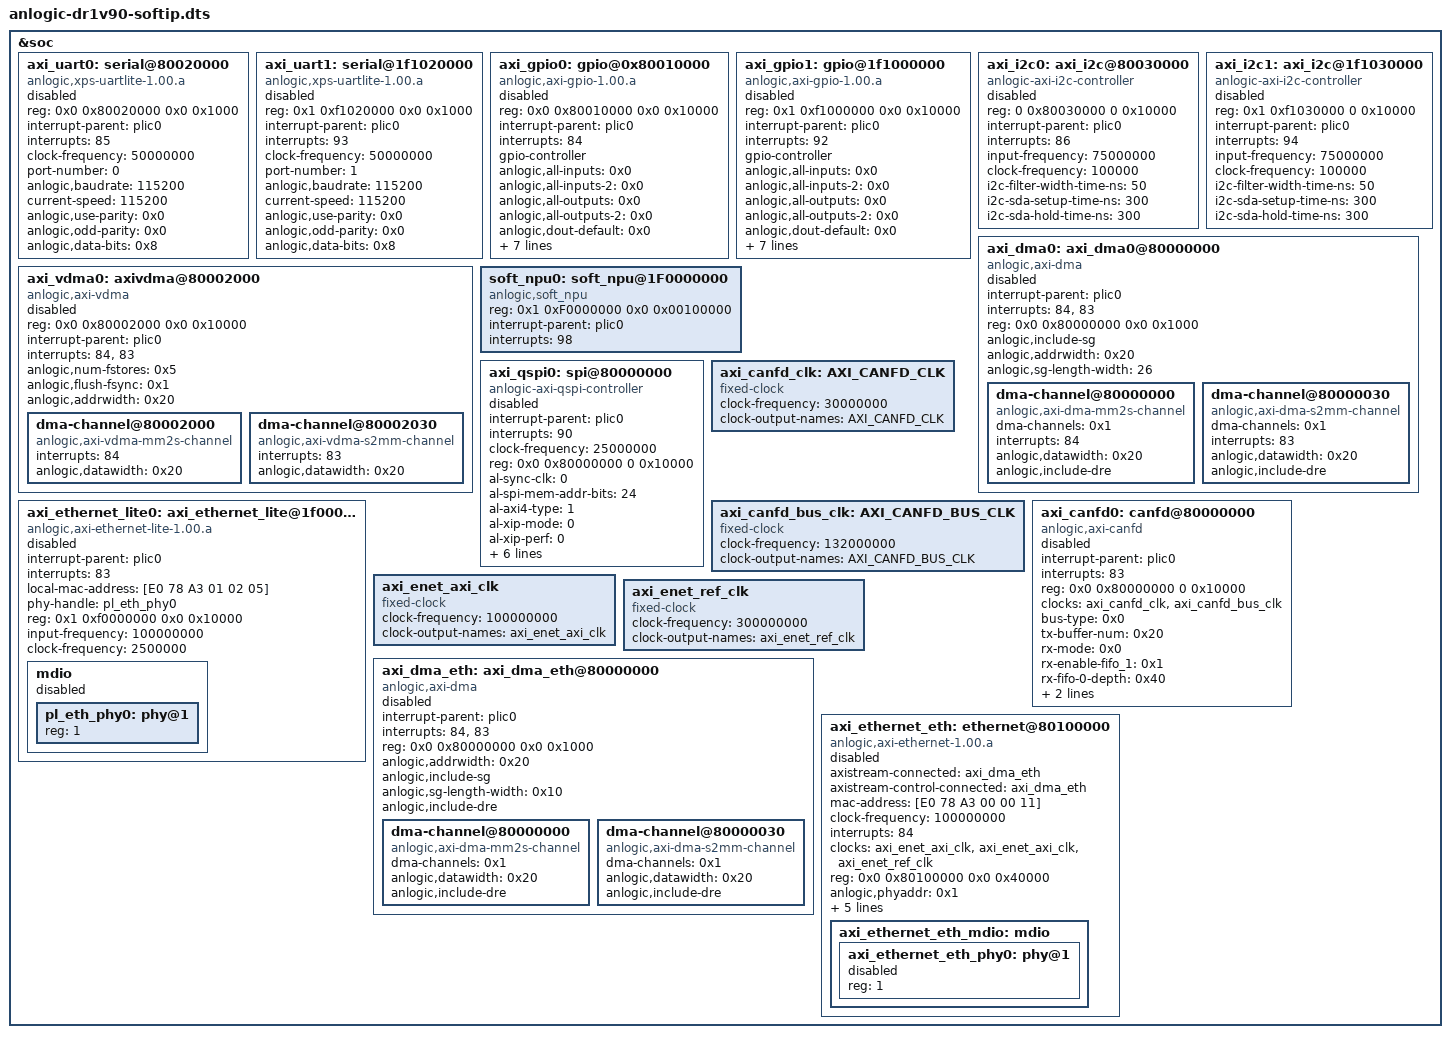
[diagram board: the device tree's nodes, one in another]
// SPDX-License-Identifier: (GPL-2.0+ OR MIT)

&soc {
	axi_uart0: serial@80020000 {
		compatible = "anlogic,xps-uartlite-1.00.a";
		reg = <0x0 0x80020000 0x0 0x1000>;
		interrupt-parent = <&plic0>;
		interrupts = <85>; /* BM 116 */
		clock-frequency = <50000000>;
		port-number = <0>;
		anlogic,baudrate = <115200>;
		current-speed = <115200>;
		anlogic,use-parity = <0x0>;
		anlogic,odd-parity = <0x0>;
		anlogic,data-bits = <0x8>;
		status = "disabled";
	};

	axi_uart1: serial@1f1020000 {
		compatible = "anlogic,xps-uartlite-1.00.a";
		reg = <0x1 0xf1020000 0x0 0x1000>;
		interrupt-parent = <&plic0>;
		interrupts = <93>; /* BM 124 */
		clock-frequency = <50000000>;
		port-number = <1>;
		anlogic,baudrate = <115200>;
		current-speed = <115200>;
		anlogic,use-parity = <0x0>;
		anlogic,odd-parity = <0x0>;
		anlogic,data-bits = <0x8>;
		status = "disabled";
	};

	axi_gpio0: gpio@0x80010000 {
		compatible = "anlogic,axi-gpio-1.00.a";
		reg = <0x0 0x80010000 0x0 0x10000>;
		interrupt-parent = <&plic0>;
		interrupts = <84>; /* BM 115 */
		#gpio-cells = <2>;
		#interrupt-cells = <0x2>;
		gpio-controller;
		anlogic,all-inputs = <0x0>;
		anlogic,all-inputs-2 = <0x0>;
		anlogic,all-outputs = <0x0>;
		anlogic,all-outputs-2 = <0x0>;
		anlogic,dout-default = <0x0>;
		anlogic,dout-default-2 = <0x0>;
		anlogic,gpio-width = <0x20>;
		anlogic,gpio2-width = <0x20>;
		anlogic,interrupt-present = <0x1>;
		anlogic,is-dual = <0x1>;
		anlogic,tri-default = <0xFFFFFFFF>;
		anlogic,tri-default-2 = <0xFFFFFFFF>;
		status = "disabled";
	};

	axi_gpio1: gpio@1f1000000 {
		compatible = "anlogic,axi-gpio-1.00.a";
		reg = <0x1 0xf1000000 0x0 0x10000>;
		interrupt-parent = <&plic0>;
		interrupts = <92>; /* BM 123 */
		#gpio-cells = <2>;
		#interrupt-cells = <0x2>;
		gpio-controller;
		anlogic,all-inputs = <0x0>;
		anlogic,all-inputs-2 = <0x0>;
		anlogic,all-outputs = <0x0>;
		anlogic,all-outputs-2 = <0x0>;
		anlogic,dout-default = <0x0>;
		anlogic,dout-default-2 = <0x0>;
		anlogic,gpio-width = <0x20>;
		anlogic,gpio2-width = <0x20>;
		anlogic,interrupt-present = <0x1>;
		anlogic,is-dual = <0x1>;
		anlogic,tri-default = <0xFFFFFFFF>;
		anlogic,tri-default-2 = <0xFFFFFFFF>;
		status = "disabled";
	};

	axi_i2c0: axi_i2c@80030000 {
		compatible = "anlogic-axi-i2c-controller";
		reg = <0 0x80030000 0 0x10000>;
		interrupt-parent = <&plic0>;
		interrupts = <86>;
		input-frequency = <75000000>;
		clock-frequency = <100000>;
		i2c-filter-width-time-ns = <50>;
		i2c-sda-setup-time-ns = <300>;
		i2c-sda-hold-time-ns = <300>;
		#address-cells = <1>;
		#size-cells = <0>;
		status = "disabled";
	};

	axi_i2c1: axi_i2c@1f1030000 {
		compatible = "anlogic-axi-i2c-controller";
		reg = <0x1 0xf1030000 0 0x10000>;
		interrupt-parent = <&plic0>;
		interrupts = <94>;
		input-frequency = <75000000>;
		clock-frequency = <100000>;
		i2c-filter-width-time-ns = <50>;
		i2c-sda-setup-time-ns = <300>;
		i2c-sda-hold-time-ns = <300>;
		#address-cells = <1>;
		#size-cells = <0>;
		status = "disabled";
	};

	axi_dma0: axi_dma0@80000000 {
		#dma-cells = <1>;
		compatible = "anlogic,axi-dma";
		interrupt-parent = <&plic0>;
		interrupts = <84>, <83>;
		reg = <0x0 0x80000000 0x0 0x1000>;
		anlogic,include-sg;
		anlogic,addrwidth = <0x20>;
		anlogic,sg-length-width = <26>;
		status = "disabled";

		dma-channel@80000000 {
			compatible = "anlogic,axi-dma-mm2s-channel";
			dma-channels = <0x1>;
			interrupts = <84>;
			anlogic,datawidth = <0x20>;
			anlogic,include-dre;
		};

		dma-channel@80000030 {
			compatible = "anlogic,axi-dma-s2mm-channel";
			dma-channels = <0x1>;
			interrupts = <83>;
			anlogic,datawidth = <0x20>;
			anlogic,include-dre;
		};
	};

	axi_vdma0: axivdma@80002000 {
		compatible = "anlogic,axi-vdma";
		#dma-cells = <1>;
		reg = <0x0 0x80002000 0x0 0x10000 >;
		interrupt-parent = <&plic0>;
		interrupts = <84>, <83>;
		anlogic,num-fstores = <0x5>;
		anlogic,flush-fsync = <0x1>;
		anlogic,addrwidth = <0x20>;
		status = "disabled";

		dma-channel@80002000 {
			compatible = "anlogic,axi-vdma-mm2s-channel";
			interrupts = <84>;
			anlogic,datawidth = <0x20>;
		} ;

		dma-channel@80002030 {
			compatible = "anlogic,axi-vdma-s2mm-channel";
			interrupts = <83>;
			anlogic,datawidth = <0x20>;
		} ;
	} ;

	soft_npu0: soft_npu@1F0000000 {
		compatible = "anlogic,soft_npu";
		reg = <0x1 0xF0000000 0x0 0x00100000>;
		interrupt-parent = <&plic0>;
		interrupts = <98>;
	};

	axi_qspi0: spi@80000000 {
		compatible = "anlogic-axi-qspi-controller";
		interrupt-parent = <&plic0>;
		interrupts = <90>;
		clock-frequency = <25000000>;
		reg = <0x0 0x80000000 0 0x10000>;
		#address-cells = <1>;
		#size-cells = <0>;
		status = "disable";

		al-sync-clk = <0>;
		al-spi-mem-addr-bits = <24>;
		al-axi4-type = <1>;
		al-xip-mode = <0>;
		al-xip-perf = <0>;
		al-fifo-depth = <256>;
		al-sck-ratio = <2>;
		al-num-ss-bits = <1>;
		al-num-trans-bits = <8>;
		al-spi-mode = <0>;
		al-spi-memory = <3>;
	};

	axi_ethernet_lite0: axi_ethernet_lite@1f0000000 {
		compatible = "anlogic,axi-ethernet-lite-1.00.a";
		device_type = "network";
		interrupt-parent = <&plic0>;
		interrupts = <83>;
		local-mac-address = [E0 78 A3 01 02 05];
		phy-handle = <&pl_eth_phy0>;
		reg = <0x1 0xf0000000 0x0 0x10000>;
		input-frequency = <100000000>;
		clock-frequency = <2500000>;
		status = "disabled";

		mdio {
			#address-cells = <1>;
			#size-cells = <0>;
			status = "disabled";
			pl_eth_phy0: phy@1 {
					device_type = "ethernet-phy";
					reg = <1>;
			} ;
		};
	};

	axi_canfd_clk: AXI_CANFD_CLK {
		#clock-cells = <0>;
		compatible = "fixed-clock";
		clock-frequency = <30000000>;
		clock-output-names = "AXI_CANFD_CLK";
	};

	axi_canfd_bus_clk: AXI_CANFD_BUS_CLK {
		#clock-cells = <0>;
		compatible = "fixed-clock";
		clock-frequency = <132000000>;
		clock-output-names = "AXI_CANFD_BUS_CLK";
	};

	axi_canfd0: canfd@80000000 {
		compatible = "anlogic,axi-canfd";
		interrupt-parent = <&plic0>;
		interrupts = <83>;
		reg = <0x0 0x80000000 0 0x10000>;
		#address-cells = <1>;
		#size-cells = <0>;
		status = "disabled";

		clocks = <&axi_canfd_clk>, <&axi_canfd_bus_clk>;
		clock-names = "can_clk", "bus_clk";
		bus-type = <0x0>;
		tx-buffer-num = <0x20>;
		rx-mode = <0x0>;
		rx-enable-fifo_1 = <0x1>;
		rx-fifo-0-depth = <0x40>;
		rx-fifo-1-depth = <0x40>;
		rx-buffer-num = <0x30>;
	};

	axi_enet_axi_clk: axi_enet_axi_clk {
		#clock-cells = <0>;
		compatible = "fixed-clock";
		clock-frequency = <100000000>;
		clock-output-names = "axi_enet_axi_clk";
	};

	axi_enet_ref_clk: axi_enet_ref_clk {
		#clock-cells = <0>;
		compatible = "fixed-clock";
		clock-frequency = <300000000>;
		clock-output-names = "axi_enet_ref_clk";
	};

	axi_dma_eth: axi_dma_eth@80000000 {
		#dma-cells = <1>;
		compatible = "anlogic,axi-dma";
		interrupt-parent = <&plic0>;
		interrupts = <84>, <83>;
		reg = <0x0 0x80000000 0x0 0x1000>;
		anlogic,addrwidth = <0x20>;
		anlogic,include-sg;
		anlogic,sg-length-width = <0x10>;
		phandle = <0xac>;
		anlogic,include-dre;
		status = "disabled";

		dma-channel@80000000 {
			compatible = "anlogic,axi-dma-mm2s-channel";
			dma-channels = <0x1>;
			anlogic,datawidth = <0x20>;
			anlogic,include-dre;
		};
		dma-channel@80000030 {
			compatible = "anlogic,axi-dma-s2mm-channel";
			dma-channels = <0x1>;
			anlogic,datawidth = <0x20>;
			anlogic,include-dre;
		};
	};

	axi_ethernet_eth: ethernet@80100000 {
		axistream-connected = <&axi_dma_eth>;
		axistream-control-connected = <&axi_dma_eth>;
		mac-address = [E0 78 A3 00 00 11];
		clock-frequency = <100000000>;
		compatible = "anlogic,axi-ethernet-1.00.a";
		device_type = "network";
		interrupts = <84>;
		clock-names = "s_axi_lite_clk", "axis_clk", "ref_clk";
		clocks = <&axi_enet_axi_clk>, <&axi_enet_axi_clk>, <&axi_enet_ref_clk>;
		reg = <0x0 0x80100000 0x0 0x40000>;
		anlogic,phyaddr = <0x1>;
		anlogic,rxcsum = <0x0>;
		anlogic,rxmem = <0x8000>;
		anlogic,txcsum = <0x0>;
		phy-mode = "gmii";
		phy-handle = <&axi_ethernet_eth_phy0>;
		status = "disabled";

		axi_ethernet_eth_mdio: mdio {
			#address-cells = <1>;
			#size-cells = <0>;
			axi_ethernet_eth_phy0: phy@1 {
				status = "disabled";
				device_type = "ethernet-phy";
				reg = <1>;
			};
		};
	};
};
